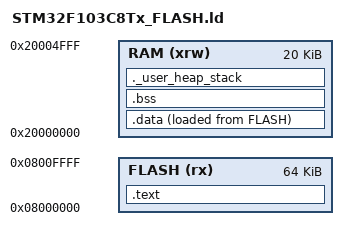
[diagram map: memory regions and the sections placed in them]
/* Entry Point */
ENTRY(Reset_Handler)

/* Highest address of the user mode stack */
_estack = ORIGIN(RAM) + LENGTH(RAM);    /* end of RAM */

/* Generate a link error if stack and heap don't fit */
_Min_Heap_Size = 0x200;      /* required amount of heap  */
_Min_Stack_Size = 0x400;     /* required amount of stack */

/* Memories definition */
MEMORY
{
  RAM    (xrw)    : ORIGIN = 0x20000000,   LENGTH = 20K
  FLASH    (rx)    : ORIGIN = 0x08000000,   LENGTH = 64K
}

/* Sections */
SECTIONS
{
  /* The startup code and other code goes into FLASH */
  .text :
  {
    . = ALIGN(4);
    *(.isr_vector)/* Startup code */
    *(.text)            /* .text sections (code) */
    *(.text*)           /* .text* sections (code) */
    *(.rodata)          /* .rodata sections (constants, strings, etc.) */
    *(.rodata*)         /* .rodata* sections */
    *(.glue7)           /* glue arm to thumb instructions */
    *(.glue7t)          /* glue thumb to arm instructions */
    *(.eh_frame)

    KEEP (*(.init))
    KEEP (*(.fini))

    . = ALIGN(4);
    _etext = .;        /* define a global symbol at end of code */
  } >FLASH

  /* Used by the startup to initialize data */
  _sidata = LOADADDR(.data);

  /* Initialized data sections goes into RAM, load LMA copied after code */
  .data : 
  {
    . = ALIGN(4);
    _sdata = .;        /* create a global symbol at data start */
    *(.data)           /* .data sections */
    *(.data*)          /* .data* sections */

    . = ALIGN(4);
    _edata = .;        /* define a global symbol at data end */
  } >RAM AT> FLASH

  /* Uninitialized data section */
  .bss :
  {
    . = ALIGN(4);
    _sbss = .;         /* define a global symbol at bss start */
    __bss_start__ = _sbss;
    *(.bss)
    *(.bss*)
    *(COMMON)

    . = ALIGN(4);
    _ebss = .;         /* define a global symbol at bss end */
    __bss_end__ = _ebss;
  } >RAM

  /* User_heap_stack section, used to check that there is enough RAM left */
  ._user_heap_stack :
  {
    . = ALIGN(8);
    PROVIDE ( end = . );
    PROVIDE ( _end = . );
    . = . + _Min_Heap_Size;
    . = . + _Min_Stack_Size;
    . = ALIGN(8);
  } >RAM

  /DISCARD/ :
  {
    *(.comment)
    *(.ARM.attributes)
  }
}
